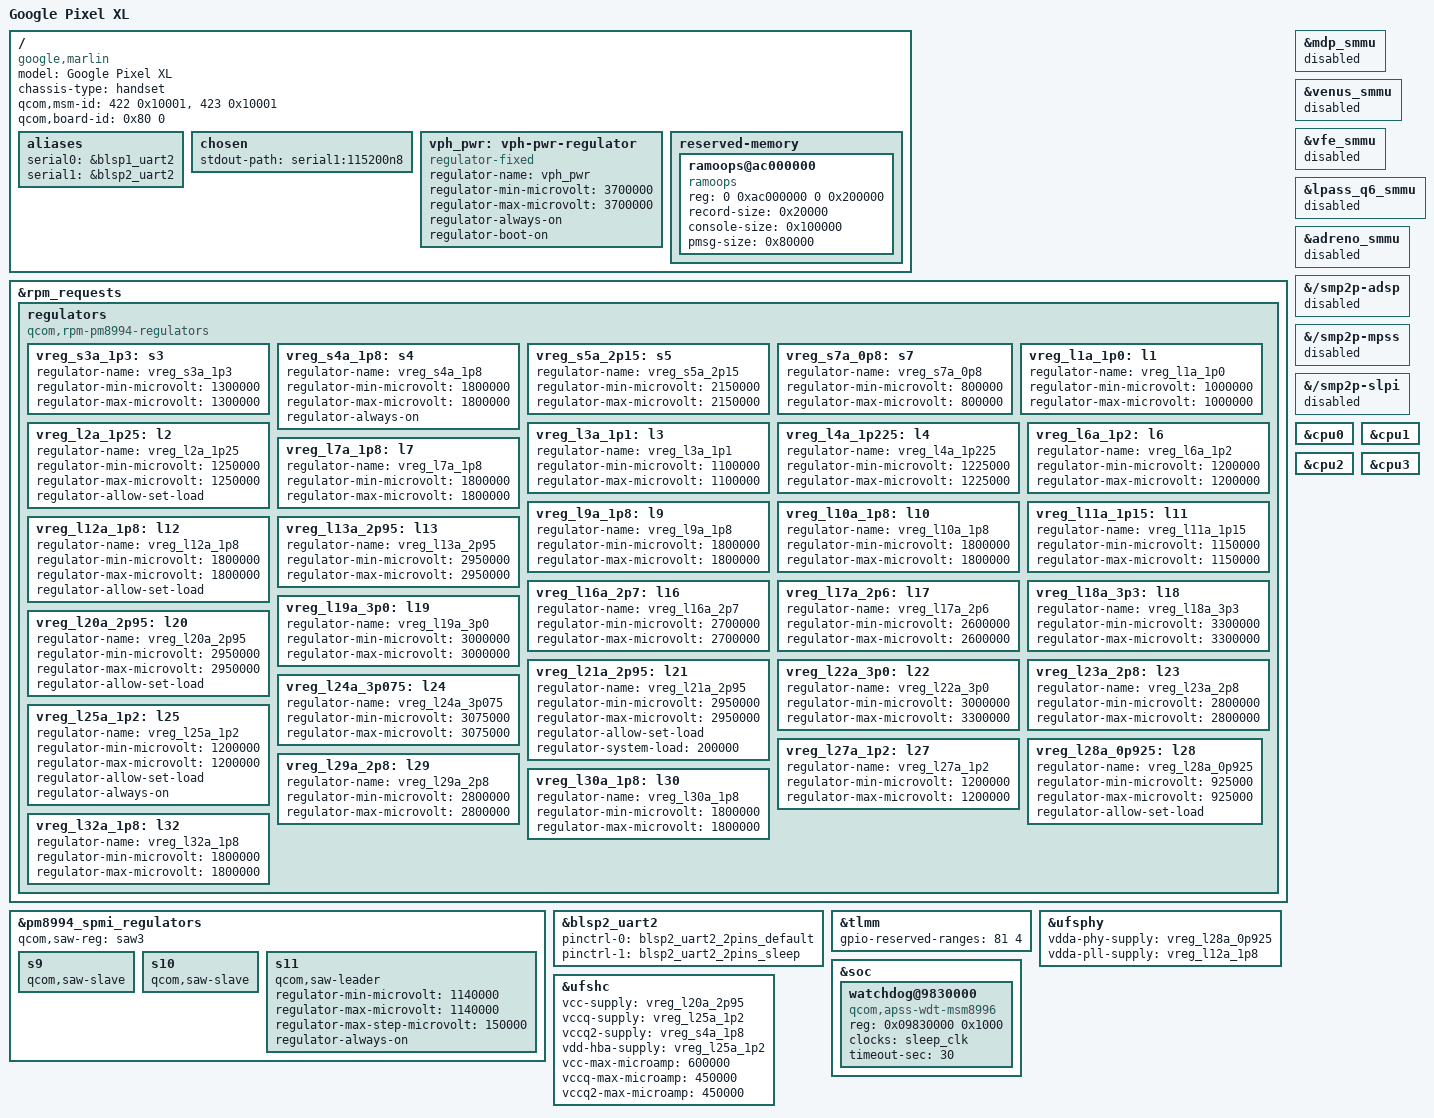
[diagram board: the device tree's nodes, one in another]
// SPDX-License-Identifier: GPL-2.0-only
/*
 * Google Pixel XL (marlin) — Qualcomm MSM8996 Pro.
 *
 * STAGE 1 bring-up, now a STANDALONE marlin device tree: the oneplus-common
 * masquerade has been removed. Earlier the board cribbed
 * msm8996-oneplus-common.dtsi wholesale (a minimal SoC+console skeleton faulted
 * before any console — it lacked the regulators/PMIC a real board carries). We
 * now carry only what marlin actually needs, built on the Pro SoC dtsi:
 *
 *  - the PM8994/PMI8994 PMICs (marlin's PMICs — the standard MSM8996 pairing);
 *  - the PM8994 RPM-managed rail map and the S11 APC SAW regulator. These rails
 *    are SoC+PMIC-level (shared by every msm8996 PM8994 board, marlin included),
 *    not board identity; voltages still want a pass against the marlin downstream
 *    dts, but they boot;
 *  - the 3.5mm-jack debug console (blsp2_uart2, pinctrl from the SoC dtsi);
 *  - the APSS watchdog;
 *  - the stage-1 SoC trims (SMMUs / DSP SMP2P / CPU DVFS).
 *
 * Everything oneplus-specific (panel, touch, camera, audio card, WiFi/PCIe, USB,
 * UFS, modem PIL, the board i2c client devices, battery, bluetooth) is simply
 * gone: those nodes are disabled-by-default in msm8996.dtsi and we no longer
 * enable them, so the long list of status="disabled" overrides is unnecessary.
 * marlin's own display/touch/etc. arrive in later stages.
 *
 * RESULT (verified on hardware 2026-07-28): boots to completion, runs Sarala
 * /init, and spawns an interactive /bin/sh whose prompt is live on the jack —
 * persistent (watchdog petted) and typable, flashed to the boot partition.
 *
 * CONSOLE: blsp2_uart2 (0x75b0000) = ttyMSM1 = the 3.5mm jack. It MUST be the
 * real console — boot with `console=ttyMSM1` — else serial_core powers it off as
 * a non-console port and the earlycon's status-register poll into the gated
 * block triggers an RPM:TZ ABORT (see first-boot.md).
 * Boot cmdline: `earlycon console=ttyMSM1,115200n8 clk_ignore_unused`
 * (stdout-path = serial1, set below).
 */
/dts-v1/;

#include "msm8996pro.dtsi"
#include "pm8994.dtsi"
#include "pmi8994.dtsi"
#include <dt-bindings/gpio/gpio.h>

/ {
	model = "Google Pixel XL";
	compatible = "google,marlin", "qcom,msm8996pro", "qcom,msm8996";
	chassis-type = "handset";

	/* aboot dtb-match IDs — confirmed from the aboot log (MSM8996 Pro v1.1). */
	qcom,msm-id = <422 0x10001>, <423 0x10001>;
	qcom,board-id = <0x80 0>;

	aliases {
		serial0 = &blsp1_uart2;
		serial1 = &blsp2_uart2;
	};

	chosen {
		stdout-path = "serial1:115200n8";
	};

	/* System (battery) rail — the input supply for the PMIC regulators. */
	vph_pwr: vph-pwr-regulator {
		compatible = "regulator-fixed";
		regulator-name = "vph_pwr";
		regulator-min-microvolt = <3700000>;
		regulator-max-microvolt = <3700000>;
		regulator-always-on;
		regulator-boot-on;
	};

	reserved-memory {
		/* pstore/ramoops — survives across the /proc/consoles check. */
		ramoops@ac000000 {
			compatible = "ramoops";
			reg = <0 0xac000000 0 0x200000>;
			record-size = <0x20000>;
			console-size = <0x100000>;
			pmsg-size = <0x80000>;
		};
	};
};

/*
 * PM8994 RPM-managed regulators — the standard msm8996 rail map (SoC+PMIC level,
 * not board identity). Carried over from the common msm8996 config; voltages to
 * be reconciled against the marlin downstream dts in a later pass.
 */
&rpm_requests {
	regulators {
		compatible = "qcom,rpm-pm8994-regulators";

		vreg_s3a_1p3: s3 {
			regulator-name = "vreg_s3a_1p3";
			regulator-min-microvolt = <1300000>;
			regulator-max-microvolt = <1300000>;
		};

		vreg_s4a_1p8: s4 {
			regulator-name = "vreg_s4a_1p8";
			regulator-min-microvolt = <1800000>;
			regulator-max-microvolt = <1800000>;
			regulator-always-on;
		};

		vreg_s5a_2p15: s5 {
			regulator-name = "vreg_s5a_2p15";
			regulator-min-microvolt = <2150000>;
			regulator-max-microvolt = <2150000>;
		};

		vreg_s7a_0p8: s7 {
			regulator-name = "vreg_s7a_0p8";
			regulator-min-microvolt = <800000>;
			regulator-max-microvolt = <800000>;
		};

		vreg_l1a_1p0: l1 {
			regulator-name = "vreg_l1a_1p0";
			regulator-min-microvolt = <1000000>;
			regulator-max-microvolt = <1000000>;
		};

		vreg_l2a_1p25: l2 {
			regulator-name = "vreg_l2a_1p25";
			regulator-min-microvolt = <1250000>;
			regulator-max-microvolt = <1250000>;
			regulator-allow-set-load;
		};

		vreg_l3a_1p1: l3 {
			regulator-name = "vreg_l3a_1p1";
			regulator-min-microvolt = <1100000>;
			regulator-max-microvolt = <1100000>;
		};

		vreg_l4a_1p225: l4 {
			regulator-name = "vreg_l4a_1p225";
			regulator-min-microvolt = <1225000>;
			regulator-max-microvolt = <1225000>;
		};

		vreg_l6a_1p2: l6 {
			regulator-name = "vreg_l6a_1p2";
			regulator-min-microvolt = <1200000>;
			regulator-max-microvolt = <1200000>;
		};

		vreg_l7a_1p8: l7 {
			regulator-name = "vreg_l7a_1p8";
			regulator-min-microvolt = <1800000>;
			regulator-max-microvolt = <1800000>;
		};

		vreg_l9a_1p8: l9 {
			regulator-name = "vreg_l9a_1p8";
			regulator-min-microvolt = <1800000>;
			regulator-max-microvolt = <1800000>;
		};

		vreg_l10a_1p8: l10 {
			regulator-name = "vreg_l10a_1p8";
			regulator-min-microvolt = <1800000>;
			regulator-max-microvolt = <1800000>;
		};

		vreg_l11a_1p15: l11 {
			regulator-name = "vreg_l11a_1p15";
			regulator-min-microvolt = <1150000>;
			regulator-max-microvolt = <1150000>;
		};

		vreg_l12a_1p8: l12 {
			regulator-name = "vreg_l12a_1p8";
			regulator-min-microvolt = <1800000>;
			regulator-max-microvolt = <1800000>;
			regulator-allow-set-load;
		};

		vreg_l13a_2p95: l13 {
			regulator-name = "vreg_l13a_2p95";
			regulator-min-microvolt = <2950000>;
			regulator-max-microvolt = <2950000>;
		};

		vreg_l16a_2p7: l16 {
			regulator-name = "vreg_l16a_2p7";
			regulator-min-microvolt = <2700000>;
			regulator-max-microvolt = <2700000>;
		};

		vreg_l17a_2p6: l17 {
			regulator-name = "vreg_l17a_2p6";
			regulator-min-microvolt = <2600000>;
			regulator-max-microvolt = <2600000>;
		};

		vreg_l18a_3p3: l18 {
			regulator-name = "vreg_l18a_3p3";
			regulator-min-microvolt = <3300000>;
			regulator-max-microvolt = <3300000>;
		};

		vreg_l19a_3p0: l19 {
			regulator-name = "vreg_l19a_3p0";
			regulator-min-microvolt = <3000000>;
			regulator-max-microvolt = <3000000>;
		};

		vreg_l20a_2p95: l20 {
			regulator-name = "vreg_l20a_2p95";
			regulator-min-microvolt = <2950000>;
			regulator-max-microvolt = <2950000>;
			regulator-allow-set-load;
		};

		vreg_l21a_2p95: l21 {
			regulator-name = "vreg_l21a_2p95";
			regulator-min-microvolt = <2950000>;
			regulator-max-microvolt = <2950000>;
			regulator-allow-set-load;
			regulator-system-load = <200000>;
		};

		vreg_l22a_3p0: l22 {
			regulator-name = "vreg_l22a_3p0";
			regulator-min-microvolt = <3000000>;
			regulator-max-microvolt = <3300000>;
		};

		vreg_l23a_2p8: l23 {
			regulator-name = "vreg_l23a_2p8";
			regulator-min-microvolt = <2800000>;
			regulator-max-microvolt = <2800000>;
		};

		vreg_l24a_3p075: l24 {
			regulator-name = "vreg_l24a_3p075";
			regulator-min-microvolt = <3075000>;
			regulator-max-microvolt = <3075000>;
		};

		vreg_l25a_1p2: l25 {
			regulator-name = "vreg_l25a_1p2";
			regulator-min-microvolt = <1200000>;
			regulator-max-microvolt = <1200000>;
			regulator-allow-set-load;
			regulator-always-on;
		};

		vreg_l27a_1p2: l27 {
			regulator-name = "vreg_l27a_1p2";
			regulator-min-microvolt = <1200000>;
			regulator-max-microvolt = <1200000>;
		};

		vreg_l28a_0p925: l28 {
			regulator-name = "vreg_l28a_0p925";
			regulator-min-microvolt = <925000>;
			regulator-max-microvolt = <925000>;
			regulator-allow-set-load;
		};

		vreg_l29a_2p8: l29 {
			regulator-name = "vreg_l29a_2p8";
			regulator-min-microvolt = <2800000>;
			regulator-max-microvolt = <2800000>;
		};

		vreg_l30a_1p8: l30 {
			regulator-name = "vreg_l30a_1p8";
			regulator-min-microvolt = <1800000>;
			regulator-max-microvolt = <1800000>;
		};

		vreg_l32a_1p8: l32 {
			regulator-name = "vreg_l32a_1p8";
			regulator-min-microvolt = <1800000>;
			regulator-max-microvolt = <1800000>;
		};

		/*
		 * NOTE: pm8994 lvs2 (a low-voltage *switch*, no voltage control) is
		 * intentionally omitted. Giving a switch regulator-min/max-microvolt
		 * makes the regulator core reject it with -EINVAL, which fails the
		 * entire qcom_rpm_smd_regulator probe and tears down *all* PM8994 rails
		 * (observed: UFS then can't get vdd-hba, defers forever). lvs2 only fed
		 * the oneplus panel vddio, which marlin doesn't use here. If a consumer
		 * ever needs it, add it back WITHOUT the voltage constraint.
		 */
	};
};


/*
 * PM8994 SPMI (SAW) regulators. s11 is the APC0/APC1 SAW leader (Kryo supply);
 * s9/s10 are its slaves. Always-on; boot depends on it.
 */
&pm8994_spmi_regulators {
	qcom,saw-reg = <&saw3>;

	s9 {
		qcom,saw-slave;
	};

	s10 {
		qcom,saw-slave;
	};

	s11 {
		qcom,saw-leader;
		regulator-min-microvolt = <1140000>;
		regulator-max-microvolt = <1140000>;
		regulator-max-step-microvolt = <150000>;
		regulator-always-on;
	};
};

/*
 * Debug console on the 3.5mm jack. blsp2_uart2 = ttyMSM1; pinctrl states come
 * from msm8996.dtsi. Must be the runtime console (console=ttyMSM1); see header.
 */
&blsp2_uart2 {
	pinctrl-names = "default", "sleep";
	pinctrl-0 = <&blsp2_uart2_2pins_default>;
	pinctrl-1 = <&blsp2_uart2_2pins_sleep>;
	status = "okay";
};

/*
 * Reserve the secure GPIO range. GPIOs 81-84 on msm8996 are owned by a secure
 * subsystem and XPU-protected; if gpiolib/pinctrl init touches them the TLMM
 * raises an XPU_VIOLATION -> RPM:TZ ABORT at ~0.6 s (XPU id 64 = TLMM). This one
 * line was in oneplus-common's &tlmm and is boot-critical — do not drop it.
 */
&tlmm {
	gpio-reserved-ranges = <81 4>;
};

/*
 * UFS storage (the boot device: /dev/sda, holds the GPT + boot_a/boot_b).
 * Needed so Sarala can read/write the A/B boot-control metadata — marlin stores
 * the slot "successful"/priority/retry bits in the GPT partition attributes, and
 * without marking the active slot successful the bootloader rolls back to stock
 * after a few boots. Supplies are the standard msm8996 UFS rails (all defined in
 * &rpm_requests above). PHY + host controller drivers are built in
 * (PHY_QCOM_QMP_UFS, SCSI_UFS_QCOM). Re-enables the SoC nodes disabled by default.
 */
&ufsphy {
	vdda-phy-supply = <&vreg_l28a_0p925>;
	vdda-pll-supply = <&vreg_l12a_1p8>;
	status = "okay";
};

&ufshc {
	vcc-supply = <&vreg_l20a_2p95>;
	vccq-supply = <&vreg_l25a_1p2>;
	vccq2-supply = <&vreg_s4a_1p8>;
	vdd-hba-supply = <&vreg_l25a_1p2>;
	vcc-max-microamp = <600000>;
	vccq-max-microamp = <450000>;
	vccq2-max-microamp = <450000>;
	status = "okay";
};

/*
 * Stage-1 SoC trims. These MMSS/LPASS IOMMUs are status="okay" (or default-on)
 * in msm8996.dtsi but their power domains are not up on a console-only boot, so
 * register access NOC-aborts. adreno_smmu is disabled defensively (its only
 * consumer, the GPU, is default-off, but it re-probes via deferred_probe).
 */
&mdp_smmu      { status = "disabled"; };
&venus_smmu    { status = "disabled"; };
&vfe_smmu      { status = "disabled"; };
&lpass_q6_smmu { status = "disabled"; };
&adreno_smmu   { status = "disabled"; };

/*
 * SMP2P IPC to the DSPs (ADSP/MPSS/SLPI). Those remotes are still running from
 * aboot and raise SMP2P interrupts; our handler NOC-aborts (async). We don't use
 * the DSPs. (No labels in the SoC dtsi, so reference by path.)
 */
&{/smp2p-adsp} { status = "disabled"; };
&{/smp2p-mpss} { status = "disabled"; };
&{/smp2p-slpi} { status = "disabled"; };

/*
 * Stage-1: disable CPU DVFS. qcom-cpufreq-nvmem's first clk_set_rate on the Kryo
 * clock reprograms the APCS PLL/mux + CBF and the vdd-apc CPR — that path
 * NOC-aborts on marlin. Dropping operating-points-v2 leaves the cores at the
 * boot frequency. Real DVFS (with CPR/vdd-apc modelled) is a later stage.
 */
&cpu0 { /delete-property/ operating-points-v2; };
&cpu1 { /delete-property/ operating-points-v2; };
&cpu2 { /delete-property/ operating-points-v2; };
&cpu3 { /delete-property/ operating-points-v2; };

/*
 * APSS non-secure watchdog. aboot arms it; qcom-wdt (with
 * CONFIG_WATCHDOG_HANDLE_BOOT_ENABLED) adopts and pings it, else NON_SECURE_WDT
 * bites ~15 s in. reg is the msm8996 APSS wdt-base 0x09830000 (beside apcs_glb);
 * NOT 0x17817000 (that is the msm8998/sdm845 layout — unmapped here, hangs the
 * CPU). Absent from mainline msm8996.dtsi, so add it on &soc. Bark/bite
 * interrupts omitted (pretimeout only). See first-boot.md.
 */
&soc {
	watchdog@9830000 {
		compatible = "qcom,apss-wdt-msm8996", "qcom,kpss-wdt";
		reg = <0x09830000 0x1000>;
		clocks = <&sleep_clk>;
		timeout-sec = <30>;
	};
};
